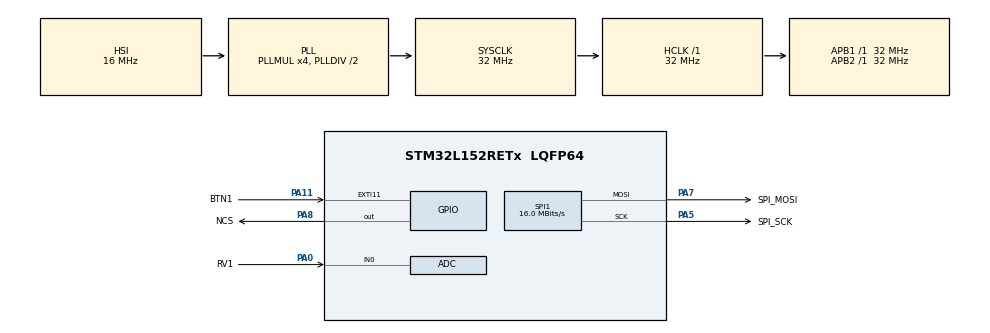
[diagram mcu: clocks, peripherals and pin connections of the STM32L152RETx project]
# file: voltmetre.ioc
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ADC.Channel-0\#ChannelRegularConversion=ADC_CHANNEL_0
ADC.NbrOfConversionFlag=1
ADC.Rank-0\#ChannelRegularConversion=1
ADC.SamplingTime-0\#ChannelRegularConversion=ADC_SAMPLETIME_4CYCLES
Mcu.Family=STM32L1
Mcu.Name=STM32L152RETx
Mcu.Package=LQFP64
NVIC.EXTI15_10_IRQn=true\:0\:0\:false\:false\:true\:true\:true\:true
NVIC.PriorityGroup=NVIC_PRIORITYGROUP_4
PA0-WKUP1.GPIO_Label=RV1
PA0-WKUP1.Mode=IN0
PA0-WKUP1.Signal=ADC_IN0
PA11.GPIO_Label=BTN1
PA11.Signal=GPXTI11
PA13.Mode=Serial_Wire
PA13.Signal=SYS_JTMS-SWDIO
PA14.Mode=Serial_Wire
PA14.Signal=SYS_JTCK-SWCLK
PA5.GPIO_Label=SPI_SCK
PA5.Mode=TX_Only_Simplex_Unidirect_Master
PA5.Signal=SPI1_SCK
PA7.GPIO_Label=SPI_MOSI
PA7.Mode=TX_Only_Simplex_Unidirect_Master
PA7.Signal=SPI1_MOSI
PA8.GPIO_Label=NCS
PA8.Signal=GPIO_Output
ProjectManager.HeapSize=0x200
ProjectManager.StackSize=0x400
ProjectManager.TargetToolchain=STM32CubeIDE
RCC.48MHZClocksFreq_Value=32000000
RCC.AHBFreq_Value=32000000
RCC.APB1Freq_Value=32000000
RCC.APB1TimFreq_Value=32000000
RCC.APB2Freq_Value=32000000
RCC.APB2TimFreq_Value=32000000
RCC.HCLKFreq_Value=32000000
RCC.HSE_VALUE=24000000
RCC.HSI_VALUE=16000000
RCC.LSE_VALUE=32768
RCC.MSI_VALUE=2097000
RCC.PLLMUL=RCC_PLL_MUL4
RCC.SYSCLKFreq_VALUE=32000000
RCC.SYSCLKSource=RCC_SYSCLKSOURCE_PLLCLK
RCC.VCOOutputFreq_Value=64000000
SPI1.CalculateBaudRate=16.0 MBits/s
SPI1.Direction=SPI_DIRECTION_2LINES
SPI1.Mode=SPI_MODE_MASTER
SPI1.VirtualType=VM_MASTER
board=custom

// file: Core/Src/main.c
/* USER CODE BEGIN Header */
/**
  ******************************************************************************
  * @file           : main.c
  * @brief          : Main program body
  ******************************************************************************
  * @attention
  *
  * Copyright (c) 2024 STMicroelectronics.
  * All rights reserved.
  *
  * This software is licensed under terms that can be found in the LICENSE file
  * in the root directory of this software component.
  * If no LICENSE file comes with this software, it is provided AS-IS.
  *
  ******************************************************************************
  */
/* USER CODE END Header */
#include "main.h"

/* USER CODE BEGIN Includes */
#include "stdio.h"
#include "stdlib.h"
/* USER CODE END Includes */

ADC_HandleTypeDef hadc;

SPI_HandleTypeDef hspi1;

void SystemClock_Config(void);
static void MX_GPIO_Init(void);
static void MX_ADC_Init(void);
static void MX_SPI1_Init(void);

/* USER CODE BEGIN 0 */
int __io_putchar(int ch){
	ITM_SendChar(ch);
	return ch;
}
/* USER CODE END 0 */

int main(void)
{

  /* MCU Configuration--------------------------------------------------------*/

  /* Reset of all peripherals, Initializes the Flash interface and the Systick. */
  HAL_Init();

  /* Configure the system clock */
  SystemClock_Config();

  /* Initialize all configured peripherals */
  MX_GPIO_Init();
  MX_ADC_Init();
  MX_SPI1_Init();
  /* USER CODE BEGIN 2 */
  main_cpp();
  /* USER CODE END 2 */

  /* Infinite loop */
  while (1)
  {

  }
}

void SystemClock_Config(void)
{
  RCC_OscInitTypeDef RCC_OscInitStruct = {0};
  RCC_ClkInitTypeDef RCC_ClkInitStruct = {0};

  /** Configure the main internal regulator output voltage
  */
  __HAL_PWR_VOLTAGESCALING_CONFIG(PWR_REGULATOR_VOLTAGE_SCALE1);

  /** Initializes the RCC Oscillators according to the specified parameters
  * in the RCC_OscInitTypeDef structure.
  */
  RCC_OscInitStruct.OscillatorType = RCC_OSCILLATORTYPE_HSI;
  RCC_OscInitStruct.HSIState = RCC_HSI_ON;
  RCC_OscInitStruct.HSICalibrationValue = RCC_HSICALIBRATION_DEFAULT;
  RCC_OscInitStruct.PLL.PLLState = RCC_PLL_ON;
  RCC_OscInitStruct.PLL.PLLSource = RCC_PLLSOURCE_HSI;
  RCC_OscInitStruct.PLL.PLLMUL = RCC_PLL_MUL4;
  RCC_OscInitStruct.PLL.PLLDIV = RCC_PLL_DIV2;
  if (HAL_RCC_OscConfig(&RCC_OscInitStruct) != HAL_OK)
  {
    Error_Handler();
  }

  /** Initializes the CPU, AHB and APB buses clocks
  */
  RCC_ClkInitStruct.ClockType = RCC_CLOCKTYPE_HCLK|RCC_CLOCKTYPE_SYSCLK
                              |RCC_CLOCKTYPE_PCLK1|RCC_CLOCKTYPE_PCLK2;
  RCC_ClkInitStruct.SYSCLKSource = RCC_SYSCLKSOURCE_PLLCLK;
  RCC_ClkInitStruct.AHBCLKDivider = RCC_SYSCLK_DIV1;
  RCC_ClkInitStruct.APB1CLKDivider = RCC_HCLK_DIV1;
  RCC_ClkInitStruct.APB2CLKDivider = RCC_HCLK_DIV1;

  if (HAL_RCC_ClockConfig(&RCC_ClkInitStruct, FLASH_LATENCY_1) != HAL_OK)
  {
    Error_Handler();
  }
}

static void MX_ADC_Init(void)
{

  ADC_ChannelConfTypeDef sConfig = {0};

  /** Configure the global features of the ADC (Clock, Resolution, Data Alignment and number of conversion)
  */
  hadc.Instance = ADC1;
  hadc.Init.ClockPrescaler = ADC_CLOCK_ASYNC_DIV1;
  hadc.Init.Resolution = ADC_RESOLUTION_12B;
  hadc.Init.DataAlign = ADC_DATAALIGN_RIGHT;
  hadc.Init.ScanConvMode = ADC_SCAN_DISABLE;
  hadc.Init.EOCSelection = ADC_EOC_SEQ_CONV;
  hadc.Init.LowPowerAutoWait = ADC_AUTOWAIT_DISABLE;
  hadc.Init.LowPowerAutoPowerOff = ADC_AUTOPOWEROFF_DISABLE;
  hadc.Init.ChannelsBank = ADC_CHANNELS_BANK_A;
  hadc.Init.ContinuousConvMode = DISABLE;
  hadc.Init.NbrOfConversion = 1;
  hadc.Init.DiscontinuousConvMode = DISABLE;
  hadc.Init.ExternalTrigConv = ADC_SOFTWARE_START;
  hadc.Init.ExternalTrigConvEdge = ADC_EXTERNALTRIGCONVEDGE_NONE;
  hadc.Init.DMAContinuousRequests = DISABLE;
  if (HAL_ADC_Init(&hadc) != HAL_OK)
  {
    Error_Handler();
  }

  /** Configure for the selected ADC regular channel its corresponding rank in the sequencer and its sample time.
  */
  sConfig.Channel = ADC_CHANNEL_0;
  sConfig.Rank = ADC_REGULAR_RANK_1;
  sConfig.SamplingTime = ADC_SAMPLETIME_4CYCLES;
  if (HAL_ADC_ConfigChannel(&hadc, &sConfig) != HAL_OK)
  {
    Error_Handler();
  }

}

static void MX_SPI1_Init(void)
{

  /* SPI1 parameter configuration*/
  hspi1.Instance = SPI1;
  hspi1.Init.Mode = SPI_MODE_MASTER;
  hspi1.Init.Direction = SPI_DIRECTION_2LINES;
  hspi1.Init.DataSize = SPI_DATASIZE_8BIT;
  hspi1.Init.CLKPolarity = SPI_POLARITY_LOW;
  hspi1.Init.CLKPhase = SPI_PHASE_1EDGE;
  hspi1.Init.NSS = SPI_NSS_SOFT;
  hspi1.Init.BaudRatePrescaler = SPI_BAUDRATEPRESCALER_2;
  hspi1.Init.FirstBit = SPI_FIRSTBIT_MSB;
  hspi1.Init.TIMode = SPI_TIMODE_DISABLE;
  hspi1.Init.CRCCalculation = SPI_CRCCALCULATION_DISABLE;
  hspi1.Init.CRCPolynomial = 10;
  if (HAL_SPI_Init(&hspi1) != HAL_OK)
  {
    Error_Handler();
  }

}

static void MX_GPIO_Init(void)
{
  GPIO_InitTypeDef GPIO_InitStruct = {0};

  /* GPIO Ports Clock Enable */
  __HAL_RCC_GPIOA_CLK_ENABLE();

  /*Configure GPIO pin Output Level */
  HAL_GPIO_WritePin(NCS_GPIO_Port, NCS_Pin, GPIO_PIN_RESET);

  /*Configure GPIO pin : NCS_Pin */
  GPIO_InitStruct.Pin = NCS_Pin;
  GPIO_InitStruct.Mode = GPIO_MODE_OUTPUT_PP;
  GPIO_InitStruct.Pull = GPIO_NOPULL;
  GPIO_InitStruct.Speed = GPIO_SPEED_FREQ_LOW;
  HAL_GPIO_Init(NCS_GPIO_Port, &GPIO_InitStruct);

  /*Configure GPIO pin : BTN1_Pin */
  GPIO_InitStruct.Pin = BTN1_Pin;
  GPIO_InitStruct.Mode = GPIO_MODE_IT_RISING;
  GPIO_InitStruct.Pull = GPIO_NOPULL;
  HAL_GPIO_Init(BTN1_GPIO_Port, &GPIO_InitStruct);

  /* EXTI interrupt init*/
  HAL_NVIC_SetPriority(EXTI15_10_IRQn, 0, 0);
  HAL_NVIC_EnableIRQ(EXTI15_10_IRQn);

}

/* USER CODE BEGIN 4 */

void HAL_GPIO_EXTI_Callback(uint16_t btn){
	//Permet d'entrer et de sortir du stop mode
	if(btn==BTN1_Pin){
			interrupt(); //Appel de la fonction interrupt

	}

}
/* USER CODE END 4 */

void Error_Handler(void)
{
  __disable_irq();
  while (1)
  {
  }
}
